# MSP430F1611 register map
Registers are 8-bit, read-write, reset 0x0 unless marked. A register's access mark holds for its fields unless they carry their own. Offsets are from the block's base; lines under a group give offsets from that group; [hi:lo] are bit positions; {n}, {i} and the like mark numbered series; 'fields as' and 'values as' point back to an identical list; <NAME> marks a mode.

## Memory map
0x00000000 SPECIAL_FUNCTION
0x00000018 PORT_3_4
0x00000020 PORT_1_2
0x00000030 PORT_5_6
0x00000050 USART_0_I2C_MODE
0x00000054 SUPPLY_VOLTAGE_SUPERVISOR
0x00000056 SYSTEM_CLOCK
0x00000058 COMPARATOR_A
0x00000070 USART_0_UART_SPI_MODE
0x00000078 USART_1
0x00000080 ADC12
0x0000011E TIMER_B7
0x00000120 WATCHDOG_TIMER
0x00000122 DMA
0x00000128 FLASH
0x0000012E TIMER_A3
0x00000130 MULTIPLIER
0x000001C0 DAC12
0x0000FFE0 _INTERRUPTS

## Interrupts
0 DACDMA (_INTERRUPTS) — 0xFFE0 DAC/DMA
1 PORT2 (_INTERRUPTS) — 0xFFE2 Port 2
2 USART1TX (_INTERRUPTS) — 0xFFE4 USART 1 Transmit
3 USART1RX (_INTERRUPTS) — 0xFFE6 USART 1 Receive
4 PORT1 (_INTERRUPTS) — 0xFFE8 Port 1
5 TIMERA1 (_INTERRUPTS) — 0xFFEA Timer A CC1-2, TA
6 TIMERA0 (_INTERRUPTS) — 0xFFEC Timer A CC0
7 ADC12 (_INTERRUPTS) — 0xFFEE ADC
8 USART0TX (_INTERRUPTS) — 0xFFF0 USART 0 Transmit
9 USART0RX (_INTERRUPTS) — 0xFFF2 USART 0 Receive
10 WDT (_INTERRUPTS) — 0xFFF4 Watchdog Timer
11 COMPARATORA (_INTERRUPTS) — 0xFFF6 Comparator A
12 TIMERB1 (_INTERRUPTS) — 0xFFF8 Timer B CC1-6, TB
13 TIMERB0 (_INTERRUPTS) — 0xFFFA Timer B CC0
14 NMI (_INTERRUPTS) — 0xFFFC Non-maskable

## Further device data
msp430_svd: version=0.3.0 commit_hash=8881b44

## SPECIAL_FUNCTION
Base 0x00000000
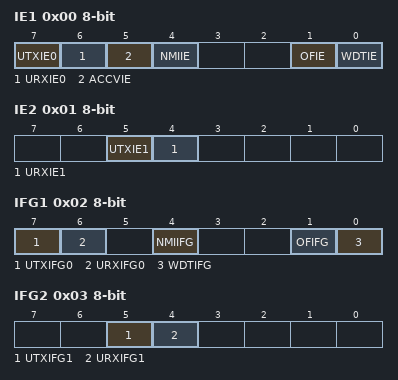
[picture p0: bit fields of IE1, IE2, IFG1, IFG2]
0x00 IE1 — Interrupt Enable 1
  [7] UTXIE0, [6] URXIE0, [5] ACCVIE, [4] NMIIE, [1] OFIE, [0] WDTIE
0x01 IE2 — Interrupt Enable 2
  [5] UTXIE1, [4] URXIE1
0x02 IFG1 — Interrupt Flag 1
  [7] UTXIFG0, [6] URXIFG0, [4] NMIIFG, [1] OFIFG, [0] WDTIFG
0x03 IFG2 — Interrupt Flag 2
  [5] UTXIFG1, [4] URXIFG1
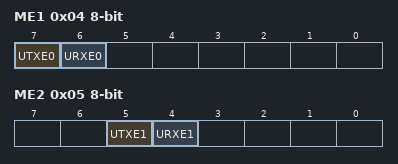
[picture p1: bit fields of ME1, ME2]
0x04 ME1 — Module Enable 1
  [7] UTXE0, [6] URXE0
0x05 ME2 — Module Enable 2
  [5] UTXE1, [4] URXE1

## PORT_3_4
Base 0x00000018
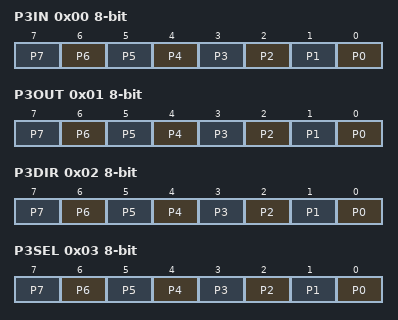
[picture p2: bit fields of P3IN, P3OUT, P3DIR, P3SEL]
0x00 P3IN — Port 3 Input
  [n] P{n} (n=0..7)
0x01 P3OUT — Port 3 Output
  [n] P{n} (n=0..7)
0x02 P3DIR — Port 3 Direction
  [n] P{n} (n=0..7)
0x03 P3SEL — Port 3 Selection
  [n] P{n} (n=0..7)
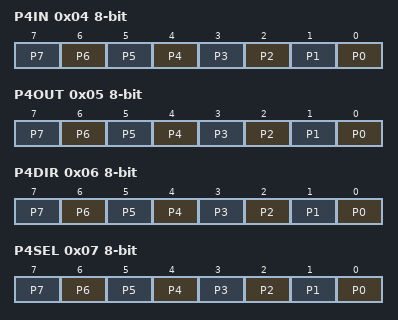
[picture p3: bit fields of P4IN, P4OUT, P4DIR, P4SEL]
0x04 P4IN — Port 4 Input
  [n] P{n} (n=0..7)
0x05 P4OUT — Port 4 Output
  [n] P{n} (n=0..7)
0x06 P4DIR — Port 4 Direction
  [n] P{n} (n=0..7)
0x07 P4SEL — Port 4 Selection
  [n] P{n} (n=0..7)

## PORT_1_2
Base 0x00000020
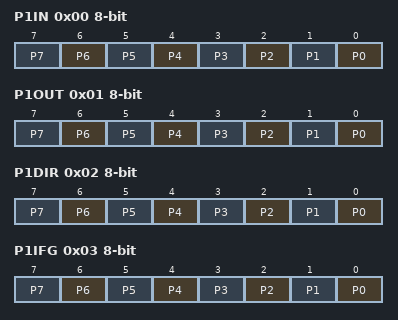
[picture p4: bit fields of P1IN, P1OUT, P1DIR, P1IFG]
0x00 P1IN — Port 1 Input
  [n] P{n} (n=0..7)
0x01 P1OUT — Port 1 Output
  [n] P{n} (n=0..7)
0x02 P1DIR — Port 1 Direction
  [n] P{n} (n=0..7)
0x03 P1IFG — Port 1 Interrupt Flag
  [n] P{n} (n=0..7)
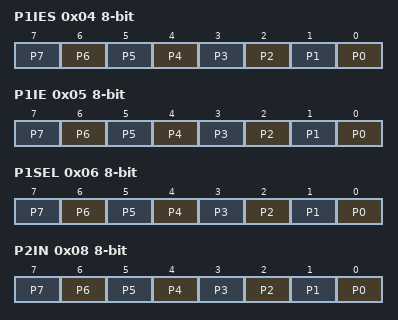
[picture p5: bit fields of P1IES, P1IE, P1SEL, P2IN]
0x04 P1IES — Port 1 Interrupt Edge Select
  [n] P{n} (n=0..7)
0x05 P1IE — Port 1 Interrupt Enable
  [n] P{n} (n=0..7)
0x06 P1SEL — Port 1 Selection
  [n] P{n} (n=0..7)
0x08 P2IN — Port 2 Input
  [n] P{n} (n=0..7)
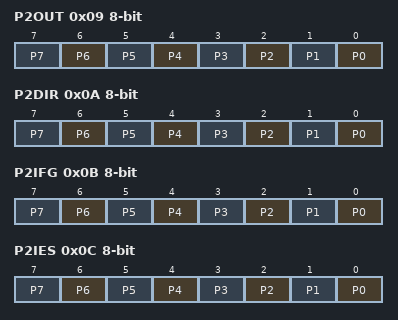
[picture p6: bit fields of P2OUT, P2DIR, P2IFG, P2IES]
0x09 P2OUT — Port 2 Output
  [n] P{n} (n=0..7)
0x0A P2DIR — Port 2 Direction
  [n] P{n} (n=0..7)
0x0B P2IFG — Port 2 Interrupt Flag
  [n] P{n} (n=0..7)
0x0C P2IES — Port 2 Interrupt Edge Select
  [n] P{n} (n=0..7)
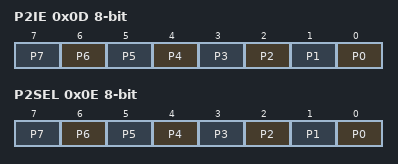
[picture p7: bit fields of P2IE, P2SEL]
0x0D P2IE — Port 2 Interrupt Enable
  [n] P{n} (n=0..7)
0x0E P2SEL — Port 2 Selection
  [n] P{n} (n=0..7)

## PORT_5_6
Base 0x00000030
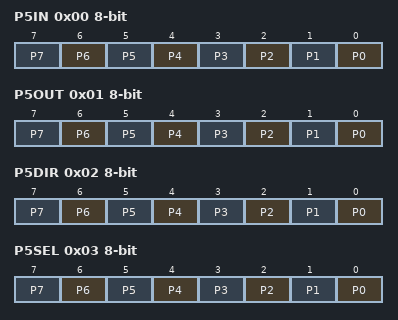
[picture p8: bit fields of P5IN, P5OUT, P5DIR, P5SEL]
0x00 P5IN — Port 5 Input
  [n] P{n} (n=0..7)
0x01 P5OUT — Port 5 Output
  [n] P{n} (n=0..7)
0x02 P5DIR — Port 5 Direction
  [n] P{n} (n=0..7)
0x03 P5SEL — Port 5 Selection
  [n] P{n} (n=0..7)
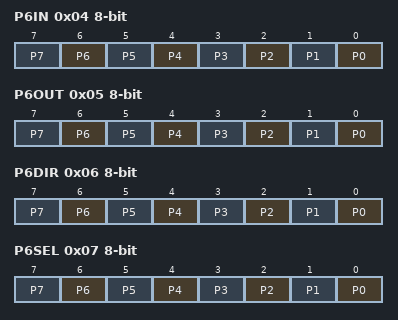
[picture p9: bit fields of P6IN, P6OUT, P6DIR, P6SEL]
0x04 P6IN — Port 6 Input
  [n] P{n} (n=0..7)
0x05 P6OUT — Port 6 Output
  [n] P{n} (n=0..7)
0x06 P6DIR — Port 6 Direction
  [n] P{n} (n=0..7)
0x07 P6SEL — Port 6 Selection
  [n] P{n} (n=0..7)

## USART_0_I2C_MODE
Base 0x00000050
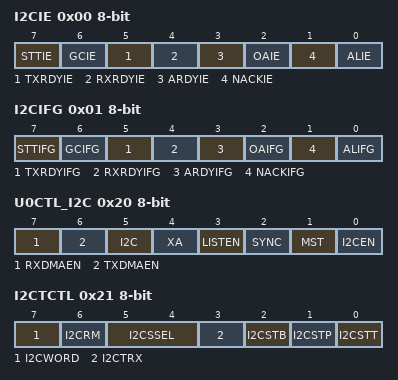
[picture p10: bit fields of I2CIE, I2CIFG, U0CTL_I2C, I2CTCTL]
0x00 I2CIE — I2C Interrupt Enable
  [7] STTIE — Start condition
  [6] GCIE — General call
  [5] TXRDYIE — Transmit ready (transmit register empty)
  [4] RXRDYIE — Receive ready (data received)
  [3] ARDYIE — Access ready (opeation complete)
  [2] OAIE — Own address
  [1] NACKIE — No acknowledge
  [0] ALIE — Arbitration lost
0x01 I2CIFG — I2C Interrupt Flag
  [7] STTIFG — Start condition
  [6] GCIFG — General call
  [5] TXRDYIFG — Transmit ready (transmit register empty)
  [4] RXRDYIFG — Receive ready (data received)
  [3] ARDYIFG — Access ready (opeation complete)
  [2] OAIFG — Own address
  [1] NACKIFG — No acknowledge
  [0] ALIFG — Arbitration lost
0x02 I2CNDAT — I2C Data Count
0x20 U0CTL_I2C — USART 0 Control I2C
  [7] RXDMAEN — Receive DMA enable
  [6] TXDMAEN — Transmit DMA enable
  [5] I2C — USART I2C
  [4] XA — I2C extended addressing
  [3] LISTEN — Loopback
  [2] SYNC — USART synchronous/asynchronous
  [1] MST — I2C master
  [0] I2CEN — I2C enable
0x21 I2CTCTL — I2C Transfer Control
  [7] I2CWORD — Word data mode
  [6] I2CRM — Repeat mode
  [5:4] I2CSSEL — Clock select bit 0
    0=I2C clock select 0: UCLK; 1=I2C clock select 1: ACLK; 2=I2C clock select 2: SMCLK; 3=I2C clock select 3: SMCLK
  [3] I2CTRX — Transmit
  [2] I2CSTB — Start byte mode
  [1] I2CSTP — Stop bit
  [0] I2CSTT — Start bit
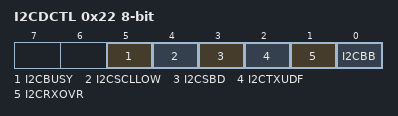
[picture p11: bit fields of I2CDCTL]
0x22 I2CDCTL — I2C Data Control
  [5] I2CBUSY — I2C Busy Flag
  [4] I2CSCLLOW — SCL being held low
  [3] I2CSBD — Received byte
  [2] I2CTXUDF — Transmit underflow
  [1] I2CRXOVR — Receiver overrun
  [0] I2CBB — Bus busy
0x23 I2CPSC — I2C Pre-scaler
0x24 I2CSCLH — I2C SCL High
0x25 I2CSCLL — I2C SCL Low
0x26 I2CDRB — I2C Data for Byte access
0xC8 I2COA 16-bit — I2C Own Address
0xCA I2CSA 16-bit — I2C Slave Address
0xCC I2CIV 16-bit — I2C Interrupt Vector
